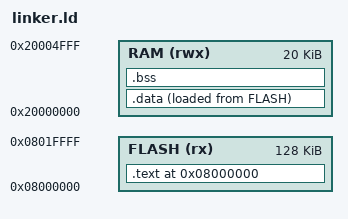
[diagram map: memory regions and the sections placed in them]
MEMORY
{
    FLASH (rx)  : ORIGIN = 0x08000000, LENGTH = 128K
    RAM   (rwx) : ORIGIN = 0x20000000, LENGTH = 20K
}

_estack = ORIGIN(RAM) + LENGTH(RAM);

SECTIONS
{
    .text 0x08000000 :
    {
        . = ALIGN(4);

        KEEP(*(.isr_vector))

        . = ALIGN(4);

        *(.text*)
        *(.rodata*)

        . = ALIGN(4);
    } > FLASH

    .data :
    {
        . = ALIGN(4);
        _sdata = .;
        *(.data*)
        . = ALIGN(4);
        _edata = .;
    } > RAM AT > FLASH

    _sidata = LOADADDR(.data);

    .bss :
    {
        . = ALIGN(4);
        _sbss = .;
        *(.bss*)
        *(COMMON)
        . = ALIGN(4);
        _ebss = .;
    } > RAM
}
